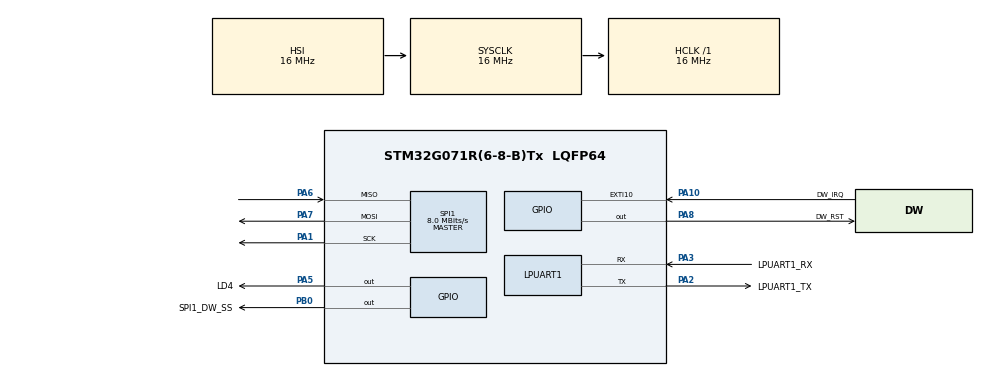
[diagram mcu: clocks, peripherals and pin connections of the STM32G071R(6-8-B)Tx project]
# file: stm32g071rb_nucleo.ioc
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Mcu.Family=STM32G0
Mcu.Name=STM32G071R(6-8-B)Tx
Mcu.Package=LQFP64
NVIC.EXTI4_15_IRQn=true\:0\:0\:false\:false\:true\:true\:true
NVIC.RCC_IRQn=true\:0\:0\:false\:false\:true\:true\:false
NVIC.SPI1_IRQn=true\:0\:0\:false\:false\:true\:true\:true
NVIC.USART3_4_LPUART1_IRQn=true\:0\:0\:false\:false\:true\:true\:true
PA1.Mode=Full_Duplex_Master
PA1.Signal=SPI1_SCK
PA10.GPIO_Label=DW_IRQ
PA10.Signal=GPXTI10
PA13.GPIO_Label=TMS
PA13.Mode=Serial_Wire
PA13.Signal=SYS_SWDIO
PA14-BOOT0.GPIO_Label=TCK
PA14-BOOT0.Mode=Serial_Wire
PA14-BOOT0.Signal=SYS_SWCLK
PA2.GPIO_Label=LPUART1_TX
PA2.Mode=Asynchronous
PA2.Signal=LPUART1_TX
PA3.GPIO_Label=LPUART1_RX
PA3.Mode=Asynchronous
PA3.Signal=LPUART1_RX
PA5.GPIO_Label=LD4
PA5.Signal=GPIO_Output
PA6.Mode=Full_Duplex_Master
PA6.Signal=SPI1_MISO
PA7.Mode=Full_Duplex_Master
PA7.Signal=SPI1_MOSI
PA8.GPIO_Label=DW_RST
PA8.Signal=GPIO_Output
PB0.GPIO_Label=SPI1_DW_SS
PB0.Signal=GPIO_Output
PC13.Mode=SYS_WakeUp1
PC13.Signal=SYS_WKUP2
PC14-OSC32_IN\ (PC14).Mode=LSE-External-Oscillator
PC14-OSC32_IN\ (PC14).Signal=RCC_OSC32_IN
PC15-OSC32_OUT\ (PC15).Mode=LSE-External-Oscillator
PC15-OSC32_OUT\ (PC15).Signal=RCC_OSC32_OUT
PF0-OSC_IN\ (PF0).GPIO_Label=MCO
PF0-OSC_IN\ (PF0).Mode=HSE-External-Clock-Source
PF0-OSC_IN\ (PF0).Signal=RCC_OSC_IN
ProjectManager.HeapSize=0x200
ProjectManager.StackSize=0x400
ProjectManager.TargetToolchain=STM32CubeIDE
RCC.AHBFreq_Value=16000000
RCC.CortexFreq_Value=16000000
RCC.EXTERNAL_CLOCK_VALUE=12288000
RCC.HCLKFreq_Value=16000000
RCC.HSE_VALUE=8000000
RCC.HSI_VALUE=16000000
RCC.SYSCLKFreq_VALUE=16000000
RCC.VCOOutputFreq_Value=128000000
SPI1.BaudRatePrescaler=SPI_BAUDRATEPRESCALER_2
SPI1.CalculateBaudRate=8.0 MBits/s
SPI1.Direction=SPI_DIRECTION_2LINES
SPI1.Mode=SPI_MODE_MASTER
SPI1.NSSPMode=SPI_NSS_PULSE_ENABLE
SPI1.VirtualType=VM_MASTER
board=NUCLEO-G071RB

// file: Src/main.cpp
/* USER CODE BEGIN Header */
/**
  ******************************************************************************
  * @file           : main.c
  * @brief          : Main program body
  ******************************************************************************
  * @attention
  *
  * <h2><center>&copy; Copyright (c) 2020 STMicroelectronics.
  * All rights reserved.</center></h2>
  *
  * This software component is licensed by ST under BSD 3-Clause license,
  * the "License"; You may not use this file except in compliance with the
  * License. You may obtain a copy of the License at:
  *                        opensource.org/licenses/BSD-3-Clause
  *
  ******************************************************************************
  */
/* USER CODE END Header */

#include "main.h"

/* USER CODE BEGIN Includes */

#include "DW1000Ng.hpp"
#include "DW1000NgUtils.hpp"
#include "DW1000NgRanging.hpp"
/* USER CODE END Includes */

UART_HandleTypeDef hlpuart1;

SPI_HandleTypeDef hspi1;

/* USER CODE BEGIN PV */
uint32_t nowTick = 0;
uint32_t pastTick = 0;

/* USER CODE END PV */

void SystemClock_Config(void);
static void MX_GPIO_Init(void);
static void MX_LPUART1_UART_Init(void);
static void MX_SPI1_Init(void);

int main(void)
{

  /* MCU Configuration--------------------------------------------------------*/

  /* Reset of all peripherals, Initializes the Flash interface and the Systick. */
  HAL_Init();

  /* Configure the system clock */
  SystemClock_Config();

  /* Initialize all configured peripherals */
  MX_GPIO_Init();
  MX_LPUART1_UART_Init();
  MX_SPI1_Init();
  /* USER CODE BEGIN 2 */

  DW1000Ng::initialize(SPI1_DW_SS_GPIO_Port, SPI1_DW_SS_Pin, DW_IRQ_GPIO_Port, DW_IRQ_Pin, DW_RST_GPIO_Port, DW_RST_Pin);
  /* USER CODE END 2 */

  /* Infinite loop */
  while (1)
  {

    /* USER CODE BEGIN 3 */
	  nowTick = HAL_GetTick();
	  	  if (nowTick - pastTick > 100)
	  	  {
	  		  HAL_GPIO_TogglePin(GPIOA, GPIO_PIN_5);
	  		  pastTick = nowTick;
	  	  }
  }
  /* USER CODE END 3 */
}

void SystemClock_Config(void)
{
  RCC_OscInitTypeDef RCC_OscInitStruct = {0};
  RCC_ClkInitTypeDef RCC_ClkInitStruct = {0};
  RCC_PeriphCLKInitTypeDef PeriphClkInit = {0};

  /** Configure the main internal regulator output voltage
  */
  HAL_PWREx_ControlVoltageScaling(PWR_REGULATOR_VOLTAGE_SCALE1);
  /** Initializes the CPU, AHB and APB busses clocks
  */
  RCC_OscInitStruct.OscillatorType = RCC_OSCILLATORTYPE_HSI;
  RCC_OscInitStruct.HSIState = RCC_HSI_ON;
  RCC_OscInitStruct.HSIDiv = RCC_HSI_DIV1;
  RCC_OscInitStruct.HSICalibrationValue = RCC_HSICALIBRATION_DEFAULT;
  RCC_OscInitStruct.PLL.PLLState = RCC_PLL_NONE;
  if (HAL_RCC_OscConfig(&RCC_OscInitStruct) != HAL_OK)
  {
    Error_Handler();
  }
  /** Initializes the CPU, AHB and APB busses clocks
  */
  RCC_ClkInitStruct.ClockType = RCC_CLOCKTYPE_HCLK|RCC_CLOCKTYPE_SYSCLK
                              |RCC_CLOCKTYPE_PCLK1;
  RCC_ClkInitStruct.SYSCLKSource = RCC_SYSCLKSOURCE_HSI;
  RCC_ClkInitStruct.AHBCLKDivider = RCC_SYSCLK_DIV1;
  RCC_ClkInitStruct.APB1CLKDivider = RCC_HCLK_DIV1;

  if (HAL_RCC_ClockConfig(&RCC_ClkInitStruct, FLASH_LATENCY_0) != HAL_OK)
  {
    Error_Handler();
  }
  /** Initializes the peripherals clocks
  */
  PeriphClkInit.PeriphClockSelection = RCC_PERIPHCLK_LPUART1;
  PeriphClkInit.Lpuart1ClockSelection = RCC_LPUART1CLKSOURCE_PCLK1;
  if (HAL_RCCEx_PeriphCLKConfig(&PeriphClkInit) != HAL_OK)
  {
    Error_Handler();
  }
}

static void MX_LPUART1_UART_Init(void)
{

  hlpuart1.Instance = LPUART1;
  hlpuart1.Init.BaudRate = 209700;
  hlpuart1.Init.WordLength = UART_WORDLENGTH_7B;
  hlpuart1.Init.StopBits = UART_STOPBITS_1;
  hlpuart1.Init.Parity = UART_PARITY_NONE;
  hlpuart1.Init.Mode = UART_MODE_TX_RX;
  hlpuart1.Init.HwFlowCtl = UART_HWCONTROL_NONE;
  hlpuart1.Init.OneBitSampling = UART_ONE_BIT_SAMPLE_DISABLE;
  hlpuart1.Init.ClockPrescaler = UART_PRESCALER_DIV1;
  hlpuart1.AdvancedInit.AdvFeatureInit = UART_ADVFEATURE_NO_INIT;
  hlpuart1.FifoMode = UART_FIFOMODE_DISABLE;
  if (HAL_UART_Init(&hlpuart1) != HAL_OK)
  {
    Error_Handler();
  }
  if (HAL_UARTEx_SetTxFifoThreshold(&hlpuart1, UART_TXFIFO_THRESHOLD_1_8) != HAL_OK)
  {
    Error_Handler();
  }
  if (HAL_UARTEx_SetRxFifoThreshold(&hlpuart1, UART_RXFIFO_THRESHOLD_1_8) != HAL_OK)
  {
    Error_Handler();
  }
  if (HAL_UARTEx_DisableFifoMode(&hlpuart1) != HAL_OK)
  {
    Error_Handler();
  }

}

static void MX_SPI1_Init(void)
{

  /* SPI1 parameter configuration*/
  hspi1.Instance = SPI1;
  hspi1.Init.Mode = SPI_MODE_MASTER;
  hspi1.Init.Direction = SPI_DIRECTION_2LINES;
  hspi1.Init.DataSize = SPI_DATASIZE_4BIT;
  hspi1.Init.CLKPolarity = SPI_POLARITY_LOW;
  hspi1.Init.CLKPhase = SPI_PHASE_1EDGE;
  hspi1.Init.NSS = SPI_NSS_SOFT;
  hspi1.Init.BaudRatePrescaler = SPI_BAUDRATEPRESCALER_2;
  hspi1.Init.FirstBit = SPI_FIRSTBIT_MSB;
  hspi1.Init.TIMode = SPI_TIMODE_DISABLE;
  hspi1.Init.CRCCalculation = SPI_CRCCALCULATION_DISABLE;
  hspi1.Init.CRCPolynomial = 7;
  hspi1.Init.CRCLength = SPI_CRC_LENGTH_DATASIZE;
  hspi1.Init.NSSPMode = SPI_NSS_PULSE_ENABLE;
  if (HAL_SPI_Init(&hspi1) != HAL_OK)
  {
    Error_Handler();
  }

}

static void MX_GPIO_Init(void)
{
  GPIO_InitTypeDef GPIO_InitStruct = {0};

  /* GPIO Ports Clock Enable */
  __HAL_RCC_GPIOC_CLK_ENABLE();
  __HAL_RCC_GPIOF_CLK_ENABLE();
  __HAL_RCC_GPIOA_CLK_ENABLE();
  __HAL_RCC_GPIOB_CLK_ENABLE();

  /*Configure GPIO pin Output Level */
  HAL_GPIO_WritePin(GPIOA, LD4_Pin|DW_RST_Pin, GPIO_PIN_RESET);

  /*Configure GPIO pin Output Level */
  HAL_GPIO_WritePin(SPI1_DW_SS_GPIO_Port, SPI1_DW_SS_Pin, GPIO_PIN_RESET);

  /*Configure GPIO pins : LD4_Pin DW_RST_Pin */
  GPIO_InitStruct.Pin = LD4_Pin|DW_RST_Pin;
  GPIO_InitStruct.Mode = GPIO_MODE_OUTPUT_PP;
  GPIO_InitStruct.Pull = GPIO_NOPULL;
  GPIO_InitStruct.Speed = GPIO_SPEED_FREQ_LOW;
  HAL_GPIO_Init(GPIOA, &GPIO_InitStruct);

  /*Configure GPIO pin : SPI1_DW_SS_Pin */
  GPIO_InitStruct.Pin = SPI1_DW_SS_Pin;
  GPIO_InitStruct.Mode = GPIO_MODE_OUTPUT_PP;
  GPIO_InitStruct.Pull = GPIO_NOPULL;
  GPIO_InitStruct.Speed = GPIO_SPEED_FREQ_LOW;
  HAL_GPIO_Init(SPI1_DW_SS_GPIO_Port, &GPIO_InitStruct);

  /*Configure GPIO pin : DW_IRQ_Pin */
  GPIO_InitStruct.Pin = DW_IRQ_Pin;
  GPIO_InitStruct.Mode = GPIO_MODE_IT_RISING;
  GPIO_InitStruct.Pull = GPIO_NOPULL;
  HAL_GPIO_Init(DW_IRQ_GPIO_Port, &GPIO_InitStruct);

  /* EXTI interrupt init*/
  HAL_NVIC_SetPriority(EXTI4_15_IRQn, 0, 0);
  HAL_NVIC_EnableIRQ(EXTI4_15_IRQn);

}

/* USER CODE BEGIN 4 */

void HAL_GPIO_EXTI_Rising_Callback(uint16_t GPIO_Pin)
{
	DW1000Ng::interruptServiceRoutine();
}

/* USER CODE END 4 */

void Error_Handler(void)
{
}

/************************ (C) COPYRIGHT STMicroelectronics *****END OF FILE****/
